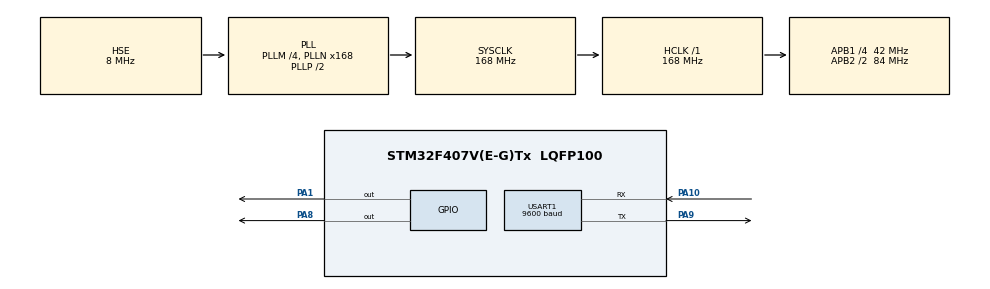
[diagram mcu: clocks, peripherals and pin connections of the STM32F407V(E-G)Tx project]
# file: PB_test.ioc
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Dma.Request0=USART1_TX
Dma.Request1=USART1_RX
Dma.USART1_RX.1.Direction=DMA_PERIPH_TO_MEMORY
Dma.USART1_RX.1.FIFOMode=DMA_FIFOMODE_DISABLE
Dma.USART1_RX.1.Instance=DMA2_Stream2
Dma.USART1_RX.1.MemDataAlignment=DMA_MDATAALIGN_BYTE
Dma.USART1_RX.1.MemInc=DMA_MINC_ENABLE
Dma.USART1_RX.1.Mode=DMA_NORMAL
Dma.USART1_RX.1.PeriphDataAlignment=DMA_PDATAALIGN_BYTE
Dma.USART1_RX.1.PeriphInc=DMA_PINC_DISABLE
Dma.USART1_RX.1.Priority=DMA_PRIORITY_LOW
Dma.USART1_TX.0.Direction=DMA_MEMORY_TO_PERIPH
Dma.USART1_TX.0.FIFOMode=DMA_FIFOMODE_DISABLE
Dma.USART1_TX.0.Instance=DMA2_Stream7
Dma.USART1_TX.0.MemDataAlignment=DMA_MDATAALIGN_BYTE
Dma.USART1_TX.0.MemInc=DMA_MINC_ENABLE
Dma.USART1_TX.0.Mode=DMA_NORMAL
Dma.USART1_TX.0.PeriphDataAlignment=DMA_PDATAALIGN_BYTE
Dma.USART1_TX.0.PeriphInc=DMA_PINC_DISABLE
Dma.USART1_TX.0.Priority=DMA_PRIORITY_LOW
Mcu.Family=STM32F4
Mcu.Name=STM32F407V(E-G)Tx
Mcu.Package=LQFP100
NVIC.DMA2_Stream2_IRQn=true\:0\:0\:false\:false\:true\:false\:true
NVIC.DMA2_Stream7_IRQn=true\:0\:0\:false\:false\:true\:false\:true
NVIC.PriorityGroup=NVIC_PRIORITYGROUP_4
NVIC.TIM5_IRQn=true\:0\:0\:false\:false\:true\:true\:true
NVIC.USART1_IRQn=true\:0\:0\:false\:false\:true\:true\:true
PA1.Signal=GPIO_Output
PA10.Mode=Asynchronous
PA10.Signal=USART1_RX
PA13.Mode=Serial_Wire
PA13.Signal=SYS_JTMS-SWDIO
PA14.Mode=Serial_Wire
PA14.Signal=SYS_JTCK-SWCLK
PA8.GPIO_ModeDefaultOutputPP=GPIO_MODE_OUTPUT_PP
PA8.GPIO_PuPd=GPIO_NOPULL
PA8.GPIO_Speed=GPIO_SPEED_FREQ_LOW
PA8.PinState=GPIO_PIN_SET
PA8.Signal=GPIO_Output
PA9.Mode=Asynchronous
PA9.Signal=USART1_TX
PH0-OSC_IN.Mode=HSE-External-Oscillator
PH0-OSC_IN.Signal=RCC_OSC_IN
PH1-OSC_OUT.Mode=HSE-External-Oscillator
PH1-OSC_OUT.Signal=RCC_OSC_OUT
ProjectManager.HeapSize=0x200
ProjectManager.StackSize=0x400
ProjectManager.TargetToolchain=STM32CubeIDE
RCC.48MHZClocksFreq_Value=84000000
RCC.AHBFreq_Value=168000000
RCC.APB1CLKDivider=RCC_HCLK_DIV4
RCC.APB1Freq_Value=42000000
RCC.APB1TimFreq_Value=84000000
RCC.APB2CLKDivider=RCC_HCLK_DIV2
RCC.APB2Freq_Value=84000000
RCC.APB2TimFreq_Value=168000000
RCC.CortexFreq_Value=168000000
RCC.HCLKFreq_Value=168000000
RCC.HSE_VALUE=8000000
RCC.HSI_VALUE=16000000
RCC.LSE_VALUE=32768
RCC.PLLM=4
RCC.PLLN=168
RCC.PLLSourceVirtual=RCC_PLLSOURCE_HSE
RCC.SYSCLKFreq_VALUE=168000000
RCC.SYSCLKSource=RCC_SYSCLKSOURCE_PLLCLK
RCC.VCOOutputFreq_Value=336000000
TIM2.Prescaler=84 - 1
TIM5.Prescaler=16800
USART1.BaudRate=9600
USART1.Parity=PARITY_EVEN
USART1.VirtualMode=VM_ASYNC
USART1.WordLength=WORDLENGTH_9B
VP_TIM2_VS_ClockSourceINT.Mode=Internal
VP_TIM5_VS_ClockSourceINT.Mode=Internal
VP_TIM5_VS_OPM.Mode=OPM_bit
board=custom

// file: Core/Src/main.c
/* USER CODE BEGIN Header */
/**
  ******************************************************************************
  * @file           : main.c
  * @brief          : Main program body
  ******************************************************************************
  * @attention
  *
  * <h2><center>&copy; Copyright (c) 2023 STMicroelectronics.
  * All rights reserved.</center></h2>
  *
  * This software component is licensed by ST under BSD 3-Clause license,
  * the "License"; You may not use this file except in compliance with the
  * License. You may obtain a copy of the License at:
  *                        opensource.org/licenses/BSD-3-Clause
  *
  ******************************************************************************
  */
/* USER CODE END Header */
#include "main.h"

/* USER CODE BEGIN Includes */
#include "pb_dp0_pcb.h"
/* USER CODE END Includes */

/* USER CODE BEGIN PTD */
uint8_t my_input_buf[256] = {0,};
uint8_t my_output_buf[256] = {0,};
/* USER CODE END PTD */

TIM_HandleTypeDef htim2;
TIM_HandleTypeDef htim5;

UART_HandleTypeDef huart1;
DMA_HandleTypeDef hdma_usart1_tx;
DMA_HandleTypeDef hdma_usart1_rx;

void SystemClock_Config(void);
static void MX_GPIO_Init(void);
static void MX_DMA_Init(void);
static void MX_USART1_UART_Init(void);
static void MX_TIM2_Init(void);
static void MX_TIM5_Init(void);

int main(void)
{

  /* MCU Configuration--------------------------------------------------------*/

  /* Reset of all peripherals, Initializes the Flash interface and the Systick. */
  HAL_Init();

  /* Configure the system clock */
  SystemClock_Config();

  /* Initialize all configured peripherals */
  MX_GPIO_Init();
  MX_DMA_Init();
  MX_USART1_UART_Init();
  MX_TIM2_Init();
  MX_TIM5_Init();
  /* USER CODE BEGIN 2 */

  dev_config.dir = OUT;
  dev_config.size = BYTE;
  dev_config.len = 8;

  slave_cfg.addr = 0x03;
  slave_cfg.speed = speed_1500K;
  slave_cfg.ident = 0x1133;
  slave_cfg.dev_cfg = dev_config;

  pb_dp0_pcb_init(&slave_cfg, my_input_buf, my_output_buf);

  /* USER CODE END 2 */

  /* Infinite loop */
  /* USER CODE BEGIN WHILE */
  while (1)
  {

	  pb_dp0_pcb();

    /* USER CODE END WHILE */

  }
}

void SystemClock_Config(void)
{
  RCC_OscInitTypeDef RCC_OscInitStruct = {0};
  RCC_ClkInitTypeDef RCC_ClkInitStruct = {0};

  /** Configure the main internal regulator output voltage
  */
  __HAL_RCC_PWR_CLK_ENABLE();
  __HAL_PWR_VOLTAGESCALING_CONFIG(PWR_REGULATOR_VOLTAGE_SCALE1);
  /** Initializes the RCC Oscillators according to the specified parameters
  * in the RCC_OscInitTypeDef structure.
  */
  RCC_OscInitStruct.OscillatorType = RCC_OSCILLATORTYPE_HSE;
  RCC_OscInitStruct.HSEState = RCC_HSE_ON;
  RCC_OscInitStruct.PLL.PLLState = RCC_PLL_ON;
  RCC_OscInitStruct.PLL.PLLSource = RCC_PLLSOURCE_HSE;
  RCC_OscInitStruct.PLL.PLLM = 4;
  RCC_OscInitStruct.PLL.PLLN = 168;
  RCC_OscInitStruct.PLL.PLLP = RCC_PLLP_DIV2;
  RCC_OscInitStruct.PLL.PLLQ = 4;
  if (HAL_RCC_OscConfig(&RCC_OscInitStruct) != HAL_OK)
  {
    Error_Handler();
  }
  /** Initializes the CPU, AHB and APB buses clocks
  */
  RCC_ClkInitStruct.ClockType = RCC_CLOCKTYPE_HCLK|RCC_CLOCKTYPE_SYSCLK
                              |RCC_CLOCKTYPE_PCLK1|RCC_CLOCKTYPE_PCLK2;
  RCC_ClkInitStruct.SYSCLKSource = RCC_SYSCLKSOURCE_PLLCLK;
  RCC_ClkInitStruct.AHBCLKDivider = RCC_SYSCLK_DIV1;
  RCC_ClkInitStruct.APB1CLKDivider = RCC_HCLK_DIV4;
  RCC_ClkInitStruct.APB2CLKDivider = RCC_HCLK_DIV2;

  if (HAL_RCC_ClockConfig(&RCC_ClkInitStruct, FLASH_LATENCY_5) != HAL_OK)
  {
    Error_Handler();
  }
}

static void MX_TIM2_Init(void)
{

  TIM_ClockConfigTypeDef sClockSourceConfig = {0};
  TIM_MasterConfigTypeDef sMasterConfig = {0};

  htim2.Instance = TIM2;
  htim2.Init.Prescaler = 84 - 1;
  htim2.Init.CounterMode = TIM_COUNTERMODE_UP;
  htim2.Init.Period = 4294967295;
  htim2.Init.ClockDivision = TIM_CLOCKDIVISION_DIV1;
  htim2.Init.AutoReloadPreload = TIM_AUTORELOAD_PRELOAD_DISABLE;
  if (HAL_TIM_Base_Init(&htim2) != HAL_OK)
  {
    Error_Handler();
  }
  sClockSourceConfig.ClockSource = TIM_CLOCKSOURCE_INTERNAL;
  if (HAL_TIM_ConfigClockSource(&htim2, &sClockSourceConfig) != HAL_OK)
  {
    Error_Handler();
  }
  sMasterConfig.MasterOutputTrigger = TIM_TRGO_RESET;
  sMasterConfig.MasterSlaveMode = TIM_MASTERSLAVEMODE_DISABLE;
  if (HAL_TIMEx_MasterConfigSynchronization(&htim2, &sMasterConfig) != HAL_OK)
  {
    Error_Handler();
  }

}

static void MX_TIM5_Init(void)
{

  TIM_ClockConfigTypeDef sClockSourceConfig = {0};
  TIM_MasterConfigTypeDef sMasterConfig = {0};

  htim5.Instance = TIM5;
  htim5.Init.Prescaler = 16800;
  htim5.Init.CounterMode = TIM_COUNTERMODE_UP;
  htim5.Init.Period = 4294967295;
  htim5.Init.ClockDivision = TIM_CLOCKDIVISION_DIV1;
  htim5.Init.AutoReloadPreload = TIM_AUTORELOAD_PRELOAD_DISABLE;
  if (HAL_TIM_Base_Init(&htim5) != HAL_OK)
  {
    Error_Handler();
  }
  sClockSourceConfig.ClockSource = TIM_CLOCKSOURCE_INTERNAL;
  if (HAL_TIM_ConfigClockSource(&htim5, &sClockSourceConfig) != HAL_OK)
  {
    Error_Handler();
  }
  if (HAL_TIM_OnePulse_Init(&htim5, TIM_OPMODE_SINGLE) != HAL_OK)
  {
    Error_Handler();
  }
  sMasterConfig.MasterOutputTrigger = TIM_TRGO_RESET;
  sMasterConfig.MasterSlaveMode = TIM_MASTERSLAVEMODE_DISABLE;
  if (HAL_TIMEx_MasterConfigSynchronization(&htim5, &sMasterConfig) != HAL_OK)
  {
    Error_Handler();
  }

}

static void MX_USART1_UART_Init(void)
{

  huart1.Instance = USART1;
  huart1.Init.BaudRate = 9600;
  huart1.Init.WordLength = UART_WORDLENGTH_9B;
  huart1.Init.StopBits = UART_STOPBITS_1;
  huart1.Init.Parity = UART_PARITY_EVEN;
  huart1.Init.Mode = UART_MODE_TX_RX;
  huart1.Init.HwFlowCtl = UART_HWCONTROL_NONE;
  huart1.Init.OverSampling = UART_OVERSAMPLING_16;
  if (HAL_UART_Init(&huart1) != HAL_OK)
  {
    Error_Handler();
  }

}

static void MX_DMA_Init(void)
{

  /* DMA controller clock enable */
  __HAL_RCC_DMA2_CLK_ENABLE();

  /* DMA interrupt init */
  /* DMA2_Stream2_IRQn interrupt configuration */
  HAL_NVIC_SetPriority(DMA2_Stream2_IRQn, 0, 0);
  HAL_NVIC_EnableIRQ(DMA2_Stream2_IRQn);
  /* DMA2_Stream7_IRQn interrupt configuration */
  HAL_NVIC_SetPriority(DMA2_Stream7_IRQn, 0, 0);
  HAL_NVIC_EnableIRQ(DMA2_Stream7_IRQn);

}

static void MX_GPIO_Init(void)
{
  GPIO_InitTypeDef GPIO_InitStruct = {0};

  /* GPIO Ports Clock Enable */
  __HAL_RCC_GPIOH_CLK_ENABLE();
  __HAL_RCC_GPIOA_CLK_ENABLE();

  /*Configure GPIO pin Output Level */
  HAL_GPIO_WritePin(GPIOA, GPIO_PIN_1, GPIO_PIN_SET);

  /*Configure GPIO pin Output Level */
  HAL_GPIO_WritePin(GPIOA, GPIO_PIN_8, GPIO_PIN_SET);

  /*Configure GPIO pins : PA1 PA8 */
  GPIO_InitStruct.Pin = GPIO_PIN_1|GPIO_PIN_8;
  GPIO_InitStruct.Mode = GPIO_MODE_OUTPUT_PP;
  GPIO_InitStruct.Pull = GPIO_NOPULL;
  GPIO_InitStruct.Speed = GPIO_SPEED_FREQ_LOW;
  HAL_GPIO_Init(GPIOA, &GPIO_InitStruct);

}

void Error_Handler(void)
{
  __disable_irq();
  while (1)
  {
  }
}

/************************ (C) COPYRIGHT STMicroelectronics *****END OF FILE****/
